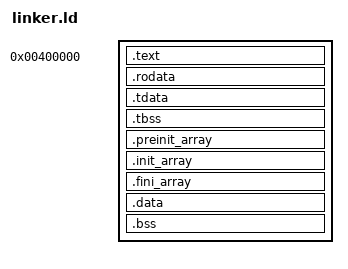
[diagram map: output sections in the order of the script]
/* Aurora user programs: static, non-PIE, loaded at 0x400000.
 * Separate segments keep text RX, rodata R and data/bss RW (the kernel's
 * loader rejects writable+executable segments). Thread-local data gets its
 * own PT_TLS header, which libc reads through AT_PHDR (0.6). */
OUTPUT_FORMAT(elf64-x86-64)
ENTRY(_start)

PHDRS
{
    text PT_LOAD FLAGS(5);
    rodata PT_LOAD FLAGS(4);
    data PT_LOAD FLAGS(6);
    tls PT_TLS FLAGS(4);
}

SECTIONS
{
    . = 0x400000;
    .text : { *(.text._start) *(.text .text.*) } :text
    . = ALIGN(4096);
    .rodata : { *(.rodata .rodata.*) *(.eh_frame*) *(.gcc_except_table*) } :rodata
    . = ALIGN(4096);
    .tdata : { *(.tdata .tdata.*) } :data :tls
    .tbss : { *(.tbss .tbss.*) } :data :tls
    .preinit_array : {
        PROVIDE_HIDDEN(__preinit_array_start = .);
        KEEP(*(.preinit_array))
        PROVIDE_HIDDEN(__preinit_array_end = .);
    } :data
    .init_array : {
        PROVIDE_HIDDEN(__init_array_start = .);
        KEEP(*(SORT_BY_INIT_PRIORITY(.init_array.*)))
        KEEP(*(.init_array))
        PROVIDE_HIDDEN(__init_array_end = .);
    } :data
    .fini_array : {
        PROVIDE_HIDDEN(__fini_array_start = .);
        KEEP(*(SORT_BY_INIT_PRIORITY(.fini_array.*)))
        KEEP(*(.fini_array))
        PROVIDE_HIDDEN(__fini_array_end = .);
    } :data
    .data : { *(.data .data.*) } :data
    .bss : { *(.bss .bss.*) *(COMMON) } :data
    /DISCARD/ : { *(.note .note.*) *(.comment) }
}
